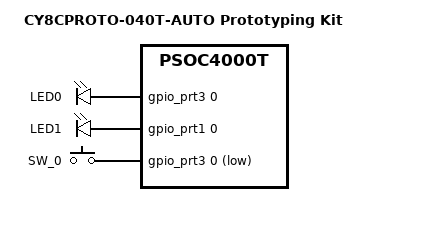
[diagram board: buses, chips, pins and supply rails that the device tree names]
/*
 * SPDX-FileCopyrightText: <text>Copyright (c) 2026 Infineon Technologies AG,
 * or an affiliate of Infineon Technologies AG. All rights reserved.</text>
 *
 * SPDX-License-Identifier: Apache-2.0
 */

/dts-v1/;
#include <arm/infineon/psoc4/mpns/cy8c4046lqi_t452.dtsi>
#include <arm/infineon/psoc4/psoc4000t/system_clocks.dtsi>
#include <zephyr/dt-bindings/input/input-event-codes.h>

#include "cy8cproto_040t_auto_common.dtsi"

/ {
	model = "CY8CPROTO-040T-AUTO Prototyping Kit";
	compatible = "infineon,cy8cproto-040t-auto", "infineon,psoc4000t";

	chosen {
		zephyr,sram = &sram0;
		zephyr,flash = &flash0;
		zephyr,console = &uart0;
		zephyr,shell-uart = &uart0;
	};

	aliases {
		led0 = &user_led2;
		led1 = &user_led3;
		sw0 = &user_bt;
	};

	leds {
		compatible = "gpio-leds";
		status = "okay";

		user_led2: led_0 {
			label = "LED0";
			gpios = <&gpio_prt3 0 GPIO_ACTIVE_HIGH>;
		};

		user_led3: led_1 {
			label = "LED1";
			gpios = <&gpio_prt1 0 GPIO_ACTIVE_HIGH>;
		};
	};

	gpio_keys {
		compatible = "gpio-keys";

		user_bt: button_0 {
			label = "SW_0";
			gpios = <&gpio_prt3 0 (GPIO_PULL_UP | GPIO_ACTIVE_LOW)>;
			zephyr,code = <INPUT_KEY_0>;
		};
	};
};
